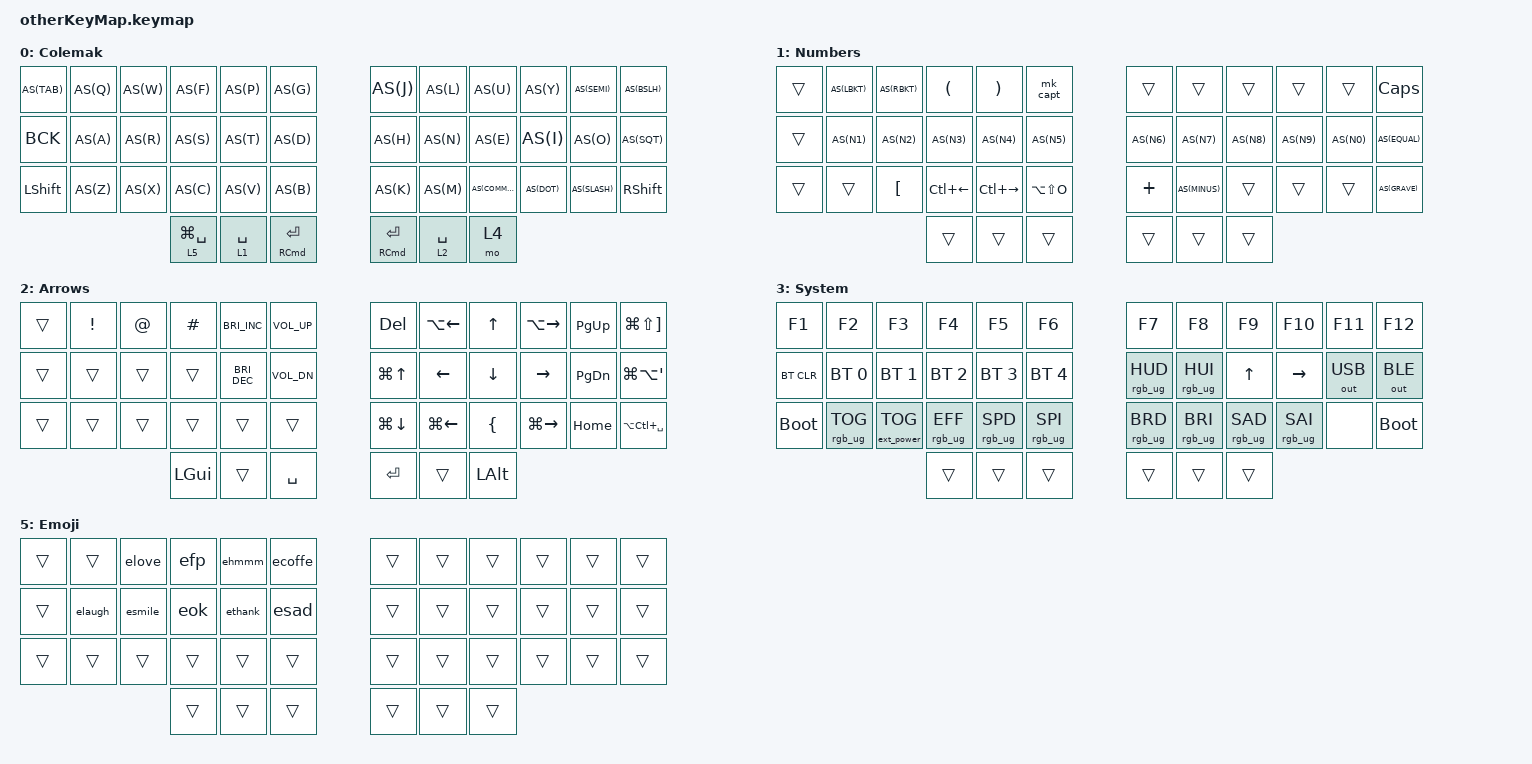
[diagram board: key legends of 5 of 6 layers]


//MACROS
        macros {
                it_egrav: it_egrav {
                        compatible = "zmk,behavior-macro";
                        #binding-cells = <0>;
                        bindings
                                = <&kp LC(LA(LG(I)))>,
                                <&macro_wait_time MACRO_WAIT_TIME>,
                                <&kp LBKT>,
                                <&macro_wait_time MACRO_WAIT_TIME>,
                                <&kp LC(LA(LG(E)))>;
                };
                it_shift_egrav: it_shift_egrav {
                        compatible = "zmk,behavior-macro";
                        #binding-cells = <0>;
                        bindings
                                = <&kp LC(LA(LG(I)))>,
                                <&macro_wait_time MACRO_WAIT_TIME>,
                                <&kp LS(LBKT)>,
                                <&macro_wait_time MACRO_WAIT_TIME>,
                                <&kp LC(LA(LG(E)))>;
                };
                it_i: it_i {
                        compatible = "zmk,behavior-macro";
                        #binding-cells = <0>;
                        bindings
                                = <&kp LC(LA(LG(I)))>,
                                <&macro_wait_time MACRO_WAIT_TIME>,
                                <&kp EQUAL>,
                                <&macro_wait_time MACRO_WAIT_TIME>,
                                <&kp LC(LA(LG(E)))>;
                };
                it_o: it_o {
                        compatible = "zmk,behavior-macro";
                        #binding-cells = <0>;
                        bindings
                                = <&kp LC(LA(LG(I)))>,
                                <&macro_wait_time MACRO_WAIT_TIME>,
                                <&kp SEMI>, 
                                <&macro_wait_time MACRO_WAIT_TIME>,
                                <&kp LC(LA(LG(E)))>;
                };
                it_u: it_u {
                        compatible = "zmk,behavior-macro";
                        #binding-cells = <0>;
                        bindings
                                = <&kp LC(LA(LG(I)))>,
                                <&macro_wait_time MACRO_WAIT_TIME>,
                                <&kp BSLH>,
                                <&macro_wait_time MACRO_WAIT_TIME>,
                                <&kp LC(LA(LG(E)))>;
                };
                it_a: it_a {
                        compatible = "zmk,behavior-macro";
                        #binding-cells = <0>;
                        bindings 
                                = <&kp LC(LA(LG(I)))>,
                                <&macro_wait_time MACRO_WAIT_TIME>,
                                <&kp SQT>,
                                <&macro_wait_time MACRO_WAIT_TIME>,
                                <&kp LC(LA(LG(E)))>;
                };
                efp: efp {
                        compatible = "zmk,behavior-macro";
                        #binding-cells = <0>;
                        bindings = <&kp UNDERSCORE &kp F &kp P>,
                                <&macro_wait_time MACRO_WAIT_TIME>;
                };
                elaugh: elaugh {
                        compatible = "zmk,behavior-macro";
                        #binding-cells = <0>;
                        bindings = <&kp UNDERSCORE &kp L &kp A>,
                                <&macro_wait_time MACRO_WAIT_TIME>;     
                };
                eok: eok {
                        compatible = "zmk,behavior-macro";
                        #binding-cells = <0>;
                        bindings = <&kp UNDERSCORE &kp O &kp K>,
                                <&macro_wait_time MACRO_WAIT_TIME>;     
                };
                ethank: ethank {
                        compatible = "zmk,behavior-macro";
                        #binding-cells = <0>;
                        bindings = <&kp UNDERSCORE &kp T &kp H>,
                                <&macro_wait_time MACRO_WAIT_TIME>;
                };
                esmile: esmile {
                        compatible = "zmk,behavior-macro";
                        #binding-cells = <0>;
                        bindings = <&kp UNDERSCORE &kp S &kp M>,
                                <&macro_wait_time MACRO_WAIT_TIME>;
                };
                esad: esad {
                        compatible = "zmk,behavior-macro";
                        #binding-cells = <0>;
                        bindings = <&kp UNDERSCORE &kp S &kp A &kp D>,
                                <&macro_wait_time MACRO_WAIT_TIME>;
                };
                elove: elove {
                        compatible = "zmk,behavior-macro";
                        #binding-cells = <0>;
                        bindings = <&kp UNDERSCORE &kp L &kp V>,
                                <&macro_wait_time MACRO_WAIT_TIME>;
                };
                ehmmm: ehmmm {
                        compatible = "zmk,behavior-macro";
                        #binding-cells = <0>;
                        bindings = <&kp UNDERSCORE &kp H &kp M>,
                                <&macro_wait_time MACRO_WAIT_TIME>;
                };
                ecoffe: ecoffe {
                        compatible = "zmk,behavior-macro";
                        #binding-cells = <0>;
                        bindings = <&kp UNDERSCORE &kp C &kp F>,
                                <&macro_wait_time MACRO_WAIT_TIME>;
                };
        };

//COMBOS
        combos {
                compatible = "zmk,combos";
                //Left CMD - ST
                combo_lcmd {
                        timeout-ms = <COMBOMS>;
                        key-positions = <15 16>;
                        bindings = <&kp LCMD>;
                };
                //Right CMD - NE
                combo_rcmd {
                        timeout-ms = <COMBOMS>;
                        key-positions = <19 20>;
                        bindings = <&kp LCMD>;
                };
                //Left ALT - RS
                combo_lalt {
                        timeout-ms = <COMBOMS>;
                        key-positions = <13 14>;
                        bindings = <&kp LALT>;
                };
                //Right ALT - EI
                combo_ralt {
                        timeout-ms = <COMBOMS>;
                        key-positions = <21 22>;
                        bindings = <&kp LALT>;
                };
                //Left CTRL - AR
                combo_lctrl {
                        timeout-ms = <COMBOMS>;
                        key-positions = <14 15>;
                        bindings = <&kp LCTRL>;
                };
                //Right CTRL - IO
                combo_rctrl {
                        timeout-ms = <COMBOMS>;
                        key-positions = <20 21>;
                        bindings = <&kp LCTRL>;
                };
                //MEH and Hyper
                                // //Left MEH - RST - 13 14 15
                                // combo_lmeh {
                                //         timeout-ms = <COMBOMS>;
                                //         key-positions = <14 15 16>;
                                //         bindings = <&kp LC(LA(LEFT_SHIFT))>;
                                // };
                                // //Right MEH - NEI - 19 20 21
                                // combo_rmeh {
                                //         timeout-ms = <COMBOMS>;
                                //         key-positions = <19 20 21>;
                                //         bindings = <&kp RC(RA(RIGHT_SHIFT))>;
                                // }; 
                                // //Left Hyper - ARST - 13 14 15 16
                                // combo_lhyp {
                                //         timeout-ms = <COMBOMS>;
                                //         key-positions = <13 14 15 16>;
                                //         bindings = <&kp LC(LA(LG(LEFT_SHIFT)))>;
                                // };
                                // //Rihgt Hyper - NEIO - 19 20 21 22
                                // combo_rhyp {
                                //         timeout-ms = <COMBOMS>;
                                //         key-positions = <19 20 21 22>;
                                //         bindings = <&kp RC(RA(RG(RIGHT_SHIFT)))>;
                                // };
                //Escape - WF
                combo_esc {
                        timeout-ms = <COMBOMS>;
                        key-positions = <2 3>;
                        bindings = <&kp ESC>;
                };
                //DEL - FP
                combo_del {
                        timeout-ms= <50>;
                        key-positions = <3 4>; 
                        bindings = <&kp DEL>;
                };
                
        };

//Behaivors
        behaviors {
        // BackSpace HOLD Tap 
                bck_ht: bck_ht {
                        compatible = "zmk,behavior-hold-tap";
                        bindings = <&kp>, <&kp>;
                        #binding-cells = <2>;
                        tapping-term-ms = <145>;    
                        quick-tap-ms = <0>;
                        require-prior-idle-ms = <140>; //initial value 140
                        flavor = "balanced";
                };
        // Hold Tap General
                ht: ht {
                        compatible = "zmk,behavior-hold-tap";
                        bindings = <&kp>, <&kp>;
                        #binding-cells = <2>;
                        tapping-term-ms = <HOLDTAP>;    
                        quick-tap-ms = <50>;
                        require-prior-idle-ms = <50>; //initial value 140
                        flavor = "balanced";
                };
        // IT_E Hold Tap
                it_e: it_e {
                        compatible = "zmk,behavior-hold-tap";
                        #binding-cells = <2>;
                        tapping-term-ms = <HOLDTAP>;
                        quick-tap-ms = <50>; // 50 I think is the sweet Spot for this settings
                        require-prior-idle-ms = <50>; // 50 I think this is the sweet spot for this settings
                        flavor = "balanced";
                        bindings = <&it_shift_egrav>, <&it_egrav>;
                };
        // Autoshift Hold Tap
                as: auto_shift {
                        compatible = "zmk,behavior-hold-tap";
                        label = "ZM_autoshift";
                        #binding-cells = <2>;
                        tapping-term-ms = <HOLDTAP>; //prev was 140
                        quick-tap-ms = <50>; // 50 I think is the sweet Spot for this settings
                        require-prior-idle-ms = <50>; // 50 I think this is the sweet spot for this settings
                        flavor = "balanced";
                        bindings = <&kp &kp>;
                };
        // Capture Screen Key TAP Dance
                mk_capt: tap_dance_mod_tap {
                        compatible = "zmk,behavior-tap-dance";
                        #binding-cells = <0>;
                        tapping-term-ms = <HOLDTAP>; //old 200
                        bindings = <&mt LG(LC(LS(N4)))  LG(LS(N2))>, <&mt LG(LS(N5))  LG(LS(N4))>;
                };
        // Double Tap for Layer 4 and HT CMD and Tap Enter
                // tap_layer4:tap_layer4 {
                //         compatible = "zmk,behavior-tap-dance";
                //         #binding-cells = <0>;
                //         tapping-term-ms =<140>;
                //         bindings = <&lt 2 SPACE>, <&mo 4>; 
                //                         // bindings = <&ht RCMD RET>, <&mo 4>;
                // };
           // Double Tap for Layer 5 Emoji and HT CMD and Tap Enter
                // tap_layer5:tap_layer5 {
                //         compatible = "zmk,behavior-tap-dance";
                //         #binding-cells = <0>;
                //         tapping-term-ms = <140>;//old was hold tap
                //         bindings = <&ht RCMD RET>, <&mo 5>;
                // };
        };
// End Behaivors

        conditional_layers {
                compatible = "zmk,conditional-layers";
                tri_layer {
                        if-layers = <1 2>;
                        then-layer = <3>;
                };
        };
 //////////-----------------------------------------------   

    keymap {
        compatible = "zmk,keymap";
//Layer 0 - Default____________________________________________________________________________________________________________________________________
        default_layer {
            display-name = "Colemak";
            bindings = <
AS(TAB)    AS(Q) AS(W) AS(F) AS(P) AS(G)                             AS(J) AS(L)  AS(U)     AS(Y)   AS(SEMI)  AS(BSLH)
BCK        AS(A) AS(R) AS(S) AS(T) AS(D)                             AS(H) AS(N)  AS(E)     AS(I)   AS(O)     AS(SQT)
&kp LSHFT  AS(Z) AS(X) AS(C) AS(V) AS(B)                             AS(K) AS(M)  AS(COMMA) AS(DOT) AS(SLASH) &kp RSHFT
        &lt 5 LG(SPACE)  &lt 1 SPACE  &ht RCMD RET             &ht RCMD RET   &lt 2 SPACE  &mo 4
                        >;
                };

//Layer 1 Numbers____________________________________________________________________________________________________________________________________
        numbers_layer {
            display-name = "Numbers";
            bindings = <
&trans       AS(LBKT)    AS(RBKT)    &kp LPAR       &kp RPAR       &mk_capt                        &trans     &trans     &trans   &trans   &trans     &kp CAPS
&trans       AS(N1)      AS(N2)      AS(N3)         AS(N4)         AS(N5)                          AS(N6)     AS(N7)     AS(N8)   AS(N9)   AS(N0)     AS(EQUAL)
&trans       &trans      &kp LBKT    &kp LC(LEFT)   &kp LC(RIGHT)  &kp LA(LS(O))                   &kp PLUS   AS(MINUS)  &trans   &trans   &trans     AS(GRAVE)  
                                                                &trans  &trans &trans         &trans  &trans  &trans
                        >;
        };
//Layer 2  Arrows Mouse __________________________________________________________________________________________________________________________________________ 
        arrows_layer {
            display-name = "Arrows";
            bindings = <
&trans &kp EXCL &kp AT &kp HASH &kp C_BRI_INC    &kp C_VOL_UP                       &kp DEL      &kp LA(LEFT)  &kp UP   &kp LA(RIGHT)  &kp PG_UP  &kp LG(LS(RBKT))
&trans &trans   &trans &trans   &kp C_BRI_DEC    &kp C_VOL_DN                       &kp LG(UP)   &kp LEFT      &kp DOWN &kp RIGHT      &kp PG_DN  &kp LG(LA(SQT))  
&trans &trans   &trans &trans   &trans    &trans                             &kp LG(DOWN) &kp LG(LEFT)  &kp LBRC &kp LG(RIGHT)  &kp HOME   &kp LA(LC(SPACE))
                            &kp LGUI  &trans   &kp SPACE                &kp RET   &trans    &kp LALT
                        >;
                };

//Layer 3   Bluetooth __________________________________________________________________________________________________________________________________________ 
        system_layer {
            display-name = "System";
            bindings = <
&kp F1        &kp F2           &kp F3              &kp F4              &kp F5              &kp F6                     &kp F7           &kp F8           &kp F9           &kp F10          &kp F11          &kp F12
&bt BT_CLR    &bt BT_SEL 0     &bt BT_SEL 1        &bt BT_SEL 2        &bt BT_SEL 3        &bt BT_SEL 4               &rgb_ug RGB_HUD  &rgb_ug RGB_HUI  &kp UP           &kp RIGHT        &out OUT_USB     &out OUT_BLE
&bootloader   &rgb_ug RGB_TOG  &ext_power EP_TOG   &rgb_ug RGB_EFF     &rgb_ug RGB_SPD     &rgb_ug RGB_SPI            &rgb_ug RGB_BRD  &rgb_ug RGB_BRI  &rgb_ug RGB_SAD  &rgb_ug RGB_SAI  &none            &bootloader 
                                                                                &trans   &trans   &trans        &trans   &trans   &trans
            >;
        };

//Layer 4 Italian Accents_______________________________________________________________________________________________________________________________________
        it_layer {
            display-name = "Italian";
            bindings = <
&trans          &trans         &trans          &trans          &trans           &trans                    &trans          &trans         &it_u           &trans           &trans            &trans
&trans          &it_a          &trans          &trans          &trans           &trans                    &trans          &trans         IT_E            &trans           &it_i             &it_o              &none
&ht LG(N1) F1   &ht LG(N2) F2  &ht LG(N3) F3   &ht LG(N4) F4   &ht LG(N5) F5    &ht LG(N6) F6             &ht LG(N7) F7   &ht LG(N8) F8  &ht LG(N9) F9   &ht LG(N0) F10   &ht LG(Z) F11    &ht LG(LS(Z)) F12
                                                                        &trans   &trans   &trans     &trans   &trans   &trans
                                >;
                };

//Layer 5 Emoji and Window Manip_________________________________________________________________________________________________________________________________
        emoji_layer {
            display-name = "Emoji";
            bindings = <
&trans   &trans    &elove   &efp     &ehmmm      &ecoffe                          &trans   &trans     &trans     &trans    &trans    &trans
&trans   &elaugh   &esmile  &eok     &ethank     &esad                            &trans   &trans     &trans     &trans    &trans    &trans
&trans   &trans    &trans   &trans   &trans      &trans                           &trans   &trans     &trans     &trans    &trans    &trans
                                            &trans   &trans   &trans        &trans   &trans   &trans
                                >;
                };
    };
};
